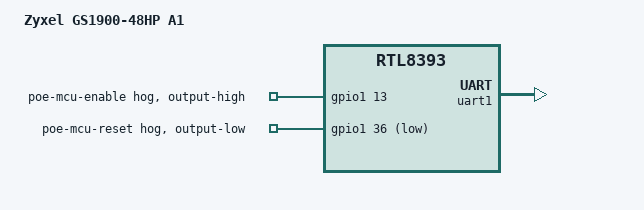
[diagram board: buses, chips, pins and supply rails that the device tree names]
// SPDX-License-Identifier: GPL-2.0-or-later

/dts-v1/;

#include "rtl8393_zyxel_gs1900-48.dtsi"

/ {
	compatible = "zyxel,gs1900-48hp-a1", "realtek,rtl8393-soc";
	model = "Zyxel GS1900-48HP A1";
};

&uart1 {
	status = "okay";
};

&gpio1 {
	poe_enable {
		gpio-hog;
		gpios = <13 GPIO_ACTIVE_HIGH>;
		output-high;
		line-name = "poe-mcu-enable";
	};

	poe_reset {
		gpio-hog;
		gpios = <36 GPIO_ACTIVE_LOW>;
		output-low;
		line-name = "poe-mcu-reset";
	};
};
